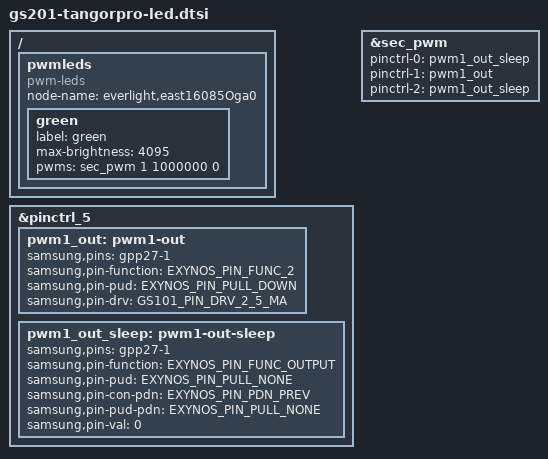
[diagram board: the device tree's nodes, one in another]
// SPDX-License-Identifier: GPL-2.0-only
/*
 * Google Tangotron-specific pwm led device tree source
 *
 * Copyright 2021 Google, LLC.
 */

#include <arm64/exynos/exynos-pinctrl.h>
#include "gs201/gs101-pinctrl.h"

/ {
	fragment@pwmleds {
		target-path = "/";
		__overlay__ {
			pwmleds {
				compatible = "pwm-leds";
				node-name = "everlight,east16085Oga0";
				green {
					label = "green";
					max-brightness = <4095>;
					pwms = <&sec_pwm 1 1000000 0>;
				};
			};
		};
	};
};

&pinctrl_5 {
	pwm1_out: pwm1-out {
		samsung,pins = "gpp27-1";
		samsung,pin-function = <EXYNOS_PIN_FUNC_2>;
		samsung,pin-pud = <EXYNOS_PIN_PULL_DOWN>;
		samsung,pin-drv = <GS101_PIN_DRV_2_5_MA>;
	};
	pwm1_out_sleep: pwm1-out-sleep {
		samsung,pins = "gpp27-1";
		samsung,pin-function = <EXYNOS_PIN_FUNC_OUTPUT>;
		samsung,pin-pud = <EXYNOS_PIN_PULL_NONE>;
		samsung,pin-con-pdn = <EXYNOS_PIN_PDN_PREV>;
		samsung,pin-pud-pdn = <EXYNOS_PIN_PULL_NONE>;
		samsung,pin-val = <0>;
	};
};

&sec_pwm {
	pinctrl-0 = <&pwm1_out_sleep>;
	pinctrl-1 = <&pwm1_out>;
	pinctrl-2 = <&pwm1_out_sleep>;
	pinctrl-names = "init", "default", "sleep";
	status = "okay";
};
